# ATSAMC21N18A register map
Registers are 32-bit, access not given, no defined reset value unless marked. A register's access mark holds for its fields unless they carry their own. Addresses are absolute; registers are grouped by the start of their names; [hi:lo] are bit positions.

## TC5
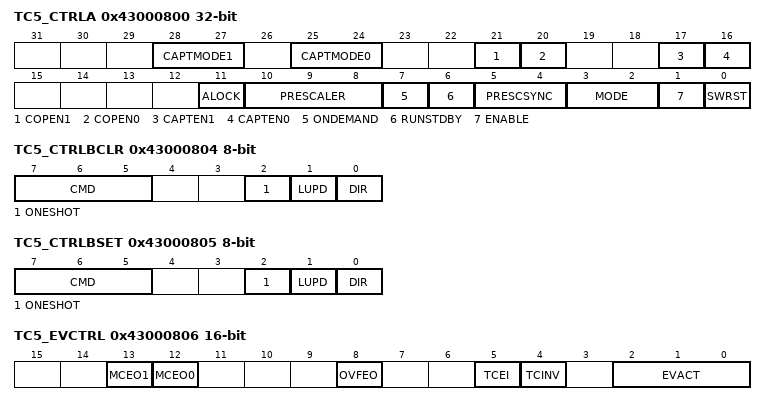
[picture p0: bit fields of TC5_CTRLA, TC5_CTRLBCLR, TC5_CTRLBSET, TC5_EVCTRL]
0x43000800 TC5_CTRLA — Control A
  [28:27] CAPTMODE1, [25:24] CAPTMODE0, [21] COPEN1, [20] COPEN0, [17] CAPTEN1, [16] CAPTEN0, [11] ALOCK, [10:8] PRESCALER, [7] ONDEMAND, [6] RUNSTDBY, [5:4] PRESCSYNC, [3:2] MODE, [1] ENABLE, [0] SWRST
0x43000804 TC5_CTRLBCLR 8-bit — Control B Clear
  [7:5] CMD, [2] ONESHOT, [1] LUPD, [0] DIR
0x43000805 TC5_CTRLBSET 8-bit — Control B Set
  [7:5] CMD, [2] ONESHOT, [1] LUPD, [0] DIR
0x43000806 TC5_EVCTRL 16-bit — Event Control
  [13] MCEO1, [12] MCEO0, [8] OVFEO, [5] TCEI, [4] TCINV, [2:0] EVACT
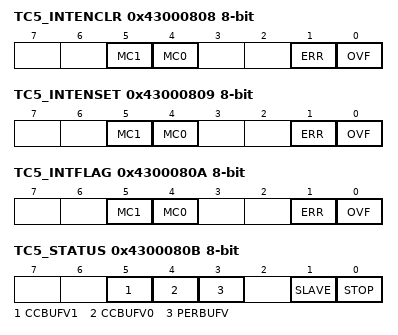
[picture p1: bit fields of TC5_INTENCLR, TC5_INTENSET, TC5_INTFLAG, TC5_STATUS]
0x43000808 TC5_INTENCLR 8-bit — Interrupt Enable Clear
  [5] MC1, [4] MC0, [1] ERR, [0] OVF
0x43000809 TC5_INTENSET 8-bit — Interrupt Enable Set
  [5] MC1, [4] MC0, [1] ERR, [0] OVF
0x4300080A TC5_INTFLAG 8-bit — Interrupt Flag Status and Clear
  [5] MC1, [4] MC0, [1] ERR, [0] OVF
0x4300080B TC5_STATUS 8-bit — Status
  [5] CCBUFV1, [4] CCBUFV0, [3] PERBUFV, [1] SLAVE, [0] STOP
0x4300080C TC5_WAVE 8-bit — Waveform Generation Control
  [1:0] WAVEGEN
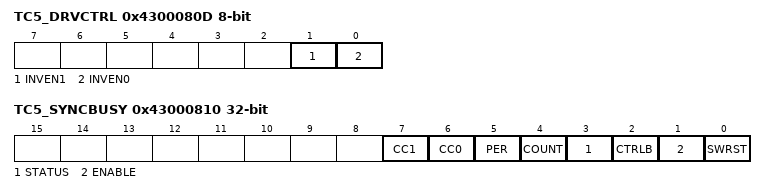
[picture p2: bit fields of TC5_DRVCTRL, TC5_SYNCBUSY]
0x4300080D TC5_DRVCTRL 8-bit — Control C
  [1] INVEN1, [0] INVEN0
0x4300080F TC5_DBGCTRL 8-bit — Debug Control
  [0] DBGRUN
0x43000810 TC5_SYNCBUSY — Synchronization Status
  [7] CC1, [6] CC0, [5] PER, [4] COUNT, [3] STATUS, [2] CTRLB, [1] ENABLE, [0] SWRST
0x43000814 TC5_COUNT_COUNT8 8-bit — COUNT8 Count
  [7:0] COUNT — Counter Value
0x43000814 TC5_COUNT_COUNT16 16-bit — COUNT16 Count
  [15:0] COUNT — Counter Value
0x43000814 TC5_COUNT_COUNT32 — COUNT32 Count
  [31:0] COUNT — Counter Value
0x4300081B TC5_PER_COUNT8 8-bit — COUNT8 Period
  [7:0] PER — Period Value
0x4300081C TC5_CC_COUNT8 8-bit — COUNT8 Compare and Capture
  [7:0] CC — Counter/Compare Value
0x4300081C TC5_CC_COUNT16 16-bit — COUNT16 Compare and Capture
  [15:0] CC — Counter/Compare Value
0x4300081C TC5_CC_COUNT32 — COUNT32 Compare and Capture
  [31:0] CC — Counter/Compare Value
0x4300082F TC5_PERBUF_COUNT8 8-bit — COUNT8 Period Buffer
  [7:0] PERBUF — Period Buffer Value
0x43000830 TC5_CCBUF_COUNT8 8-bit — COUNT8 Compare and Capture Buffer
  [7:0] CCBUF — Counter/Compare Buffer Value
0x43000830 TC5_CCBUF_COUNT16 16-bit — COUNT16 Compare and Capture Buffer
  [15:0] CCBUF — Counter/Compare Buffer Value
0x43000830 TC5_CCBUF_COUNT32 — COUNT32 Compare and Capture Buffer
  [31:0] CCBUF — Counter/Compare Buffer Value

## TC6
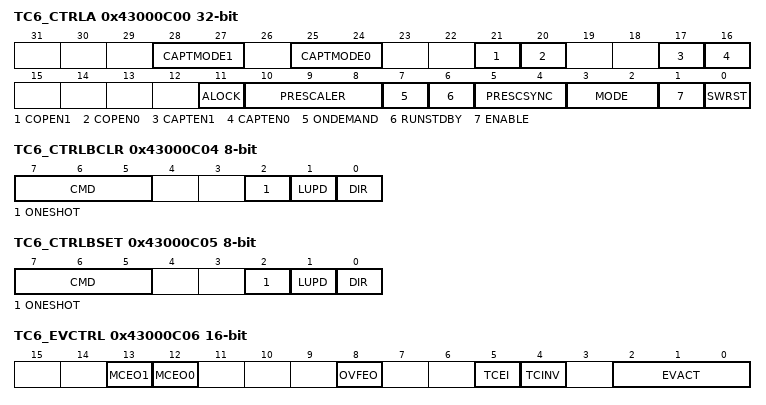
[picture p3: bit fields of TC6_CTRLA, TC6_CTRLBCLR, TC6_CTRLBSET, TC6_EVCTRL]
0x43000C00 TC6_CTRLA — Control A
  [28:27] CAPTMODE1, [25:24] CAPTMODE0, [21] COPEN1, [20] COPEN0, [17] CAPTEN1, [16] CAPTEN0, [11] ALOCK, [10:8] PRESCALER, [7] ONDEMAND, [6] RUNSTDBY, [5:4] PRESCSYNC, [3:2] MODE, [1] ENABLE, [0] SWRST
0x43000C04 TC6_CTRLBCLR 8-bit — Control B Clear
  [7:5] CMD, [2] ONESHOT, [1] LUPD, [0] DIR
0x43000C05 TC6_CTRLBSET 8-bit — Control B Set
  [7:5] CMD, [2] ONESHOT, [1] LUPD, [0] DIR
0x43000C06 TC6_EVCTRL 16-bit — Event Control
  [13] MCEO1, [12] MCEO0, [8] OVFEO, [5] TCEI, [4] TCINV, [2:0] EVACT
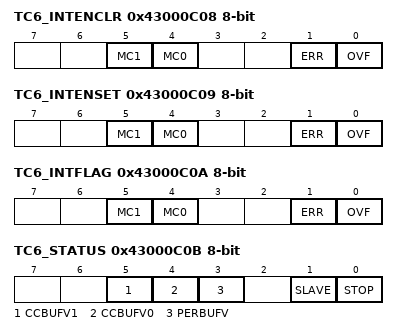
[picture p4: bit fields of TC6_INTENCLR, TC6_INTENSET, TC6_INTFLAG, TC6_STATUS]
0x43000C08 TC6_INTENCLR 8-bit — Interrupt Enable Clear
  [5] MC1, [4] MC0, [1] ERR, [0] OVF
0x43000C09 TC6_INTENSET 8-bit — Interrupt Enable Set
  [5] MC1, [4] MC0, [1] ERR, [0] OVF
0x43000C0A TC6_INTFLAG 8-bit — Interrupt Flag Status and Clear
  [5] MC1, [4] MC0, [1] ERR, [0] OVF
0x43000C0B TC6_STATUS 8-bit — Status
  [5] CCBUFV1, [4] CCBUFV0, [3] PERBUFV, [1] SLAVE, [0] STOP
0x43000C0C TC6_WAVE 8-bit — Waveform Generation Control
  [1:0] WAVEGEN
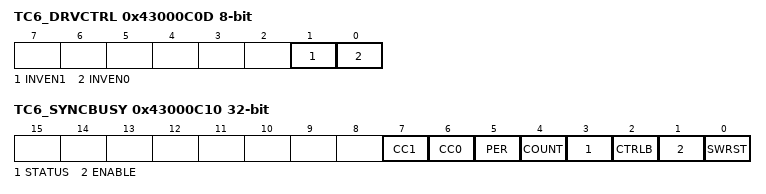
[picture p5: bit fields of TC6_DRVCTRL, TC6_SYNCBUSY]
0x43000C0D TC6_DRVCTRL 8-bit — Control C
  [1] INVEN1, [0] INVEN0
0x43000C0F TC6_DBGCTRL 8-bit — Debug Control
  [0] DBGRUN
0x43000C10 TC6_SYNCBUSY — Synchronization Status
  [7] CC1, [6] CC0, [5] PER, [4] COUNT, [3] STATUS, [2] CTRLB, [1] ENABLE, [0] SWRST
0x43000C14 TC6_COUNT_COUNT8 8-bit — COUNT8 Count
  [7:0] COUNT — Counter Value
0x43000C14 TC6_COUNT_COUNT16 16-bit — COUNT16 Count
  [15:0] COUNT — Counter Value
0x43000C14 TC6_COUNT_COUNT32 — COUNT32 Count
  [31:0] COUNT — Counter Value
0x43000C1B TC6_PER_COUNT8 8-bit — COUNT8 Period
  [7:0] PER — Period Value
0x43000C1C TC6_CC_COUNT8 8-bit — COUNT8 Compare and Capture
  [7:0] CC — Counter/Compare Value
0x43000C1C TC6_CC_COUNT16 16-bit — COUNT16 Compare and Capture
  [15:0] CC — Counter/Compare Value
0x43000C1C TC6_CC_COUNT32 — COUNT32 Compare and Capture
  [31:0] CC — Counter/Compare Value
0x43000C2F TC6_PERBUF_COUNT8 8-bit — COUNT8 Period Buffer
  [7:0] PERBUF — Period Buffer Value
0x43000C30 TC6_CCBUF_COUNT8 8-bit — COUNT8 Compare and Capture Buffer
  [7:0] CCBUF — Counter/Compare Buffer Value
0x43000C30 TC6_CCBUF_COUNT16 16-bit — COUNT16 Compare and Capture Buffer
  [15:0] CCBUF — Counter/Compare Buffer Value
0x43000C30 TC6_CCBUF_COUNT32 — COUNT32 Compare and Capture Buffer
  [31:0] CCBUF — Counter/Compare Buffer Value
